# CH641 register map
Vendor: WCH Ltd.; File version: 1.0
Registers are 32-bit, read-write, reset 0x0 unless marked. A register's access mark holds for its fields unless they carry their own. Offsets are from the block's base; [hi:lo] are bit positions; {n}, {i} and the like mark numbered series; 'fields as' and 'values as' point back to an identical list.

## AFIO — Alternate function I/O
Base 0x40010000
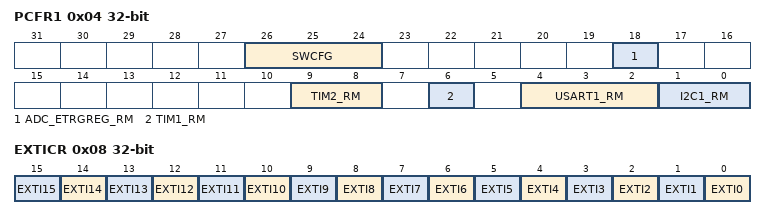
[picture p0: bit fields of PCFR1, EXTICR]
0x04 PCFR1 access per field — AF remap and debug I/O configuration register (AFIO_PCFR1)
  [26:24] SWCFG wo — Serial wire JTAG configuration
  [18] ADC_ETRGREG_RM rw — ADC External trigger injected conversion remapping
  [9:8] TIM2_RM rw — TIM2 remapping
  [6] TIM1_RM rw — TIM1 remapping
  [4:2] USART1_RM rw — USART1 remapping
  [1:0] I2C1_RM rw — I2C1 remapping
0x08 EXTICR — External interrupt configuration register (AFIO_EXTICR)
  [n] EXTI{n} (n=0..15) — EXTI{n} configuration

## EXTI
Base 0x40010400
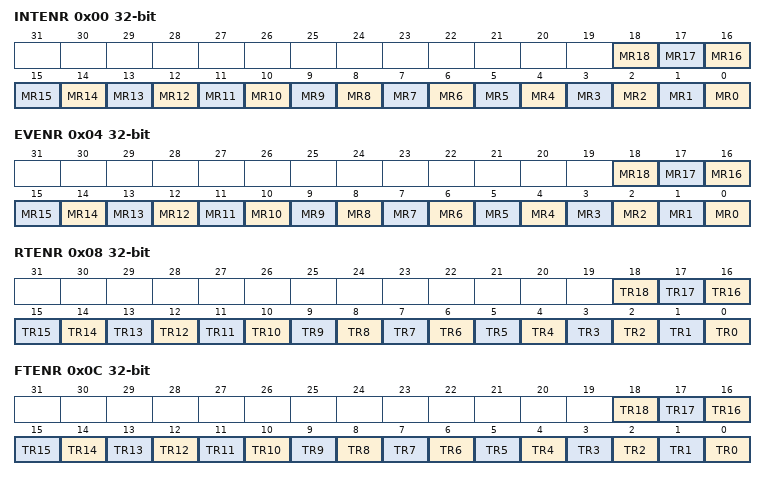
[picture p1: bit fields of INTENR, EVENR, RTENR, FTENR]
0x00 INTENR — Interrupt mask register (EXTI_INTENR)
  [n] MR{n} (n=0..18) — Interrupt Mask on line {n}
0x04 EVENR — Event mask register (EXTI_EVENR)
  [n] MR{n} (n=0..18) — Event Mask on line {n}
0x08 RTENR — Rising Trigger selection register (EXTI_RTENR)
  [n] TR{n} (n=0..18) — Rising trigger event configuration of line {n}
0x0C FTENR — Falling Trigger selection register (EXTI_FTENR)
  [n] TR{n} (n=0..18) — Falling trigger event configuration of line {n}
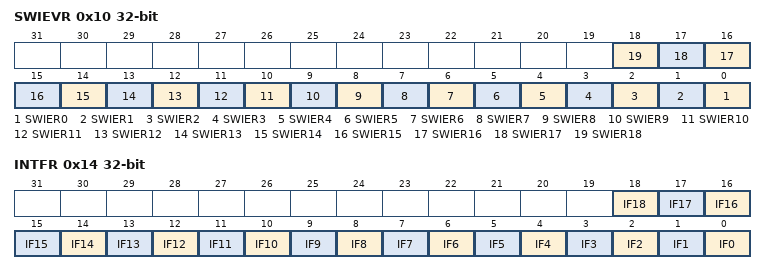
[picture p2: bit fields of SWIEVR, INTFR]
0x10 SWIEVR — Software interrupt event register (EXTI_SWIEVR)
  [n] SWIER{n} (n=0..18) — Software Interrupt on line {n}
0x14 INTFR — Pending register (EXTI_INTFR)
  [n] IF{n} (n=0..18) — Pending bit {n}

## DMA1 — DMA1 controller
Base 0x40020000
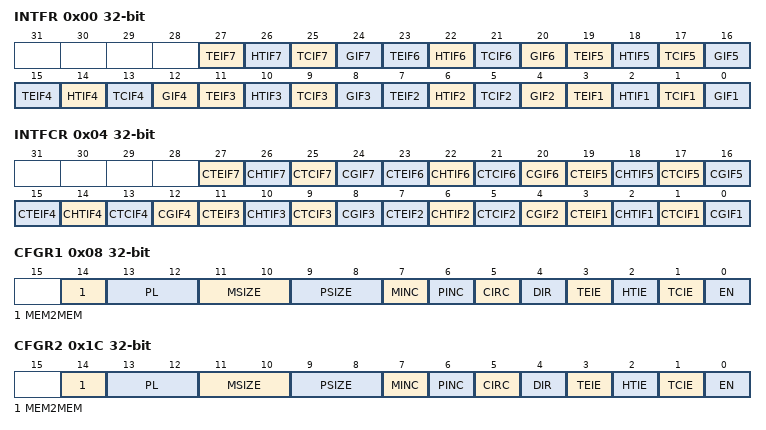
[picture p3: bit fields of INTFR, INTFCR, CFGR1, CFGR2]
0x00 INTFR ro — DMA interrupt status register (DMA_INTFR)
  [4n-1] TEIF{n} (n=1..7) — Channel {n} Transfer Error flag
  [4n-2] HTIF{n} (n=1..7) — Channel {n} Half Transfer Complete flag
  [4n-3] TCIF{n} (n=1..7) — Channel {n} Transfer Complete flag
  [4n-4] GIF{n} (n=1..7) — Channel {n} Global interrupt flag
0x04 INTFCR wo — DMA interrupt flag clear register (DMA_INTFCR)
  [4n-1] CTEIF{n} (n=1..7) — Channel {n} Transfer Error clear
  [4n-2] CHTIF{n} (n=1..7) — Channel {n} Half Transfer clear
  [4n-3] CTCIF{n} (n=1..7) — Channel {n} Transfer Complete clear
  [4n-4] CGIF{n} (n=1..7) — Channel {n} Global interrupt clear
0x08 CFGR1 — DMA channel configuration register (DMA_CFGR)
  [14] MEM2MEM — Memory to memory mode
  [13:12] PL — Channel Priority level
  [11:10] MSIZE — Memory size
  [9:8] PSIZE — Peripheral size
  [7] MINC — Memory increment mode
  [6] PINC — Peripheral increment mode
  [5] CIRC — Circular mode
  [4] DIR — Data transfer direction
  [3] TEIE — Transfer error interrupt enable
  [2] HTIE — Half Transfer interrupt enable
  [1] TCIE — Transfer complete interrupt enable
  [0] EN — Channel enable
0x0C CNTR1 — DMA channel 1 number of data register
  [15:0] NDT — Number of data to transfer
0x10 PADDR1 — DMA channel 1 peripheral address register
  [31:0] PA — Peripheral address
{0x0+0x14*i} MADDR{i} (i=1..7) — DMA channel {i} memory address register
  [31:0] MA — Memory address
0x1C CFGR2 — DMA channel configuration register (DMA_CFGR)
  fields as CFGR1
0x20 CNTR2 — DMA channel 2 number of data register
  [15:0] NDT — Number of data to transfer
0x24 PADDR2 — DMA channel 2 peripheral address register
  [31:0] PA — Peripheral address
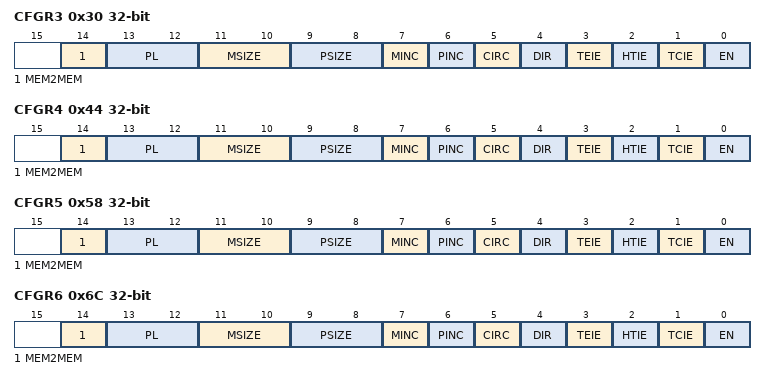
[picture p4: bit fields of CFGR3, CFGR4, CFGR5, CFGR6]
0x30 CFGR3 — DMA channel configuration register (DMA_CFGR)
  fields as CFGR1
0x34 CNTR3 — DMA channel 3 number of data register
  [15:0] NDT — Number of data to transfer
0x38 PADDR3 — DMA channel 3 peripheral address register
  [31:0] PA — Peripheral address
0x44 CFGR4 — DMA channel configuration register (DMA_CFGR)
  fields as CFGR1
0x48 CNTR4 — DMA channel 4 number of data register
  [15:0] NDT — Number of data to transfer
0x4C PADDR4 — DMA channel 4 peripheral address register
  [31:0] PA — Peripheral address
0x58 CFGR5 — DMA channel configuration register (DMA_CFGR)
  fields as CFGR1
0x5C CNTR5 — DMA channel 5 number of data register
  [15:0] NDT — Number of data to transfer
0x60 PADDR5 — DMA channel 5 peripheral address register
  [31:0] PA — Peripheral address
0x6C CFGR6 — DMA channel configuration register (DMA_CFGR)
  fields as CFGR1
0x70 CNTR6 — DMA channel 6 number of data register
  [15:0] NDT — Number of data to transfer
0x74 PADDR6 — DMA channel 6 peripheral address register
  [31:0] PA — Peripheral address
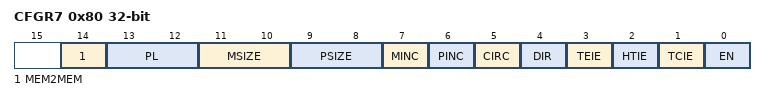
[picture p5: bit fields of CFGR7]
0x80 CFGR7 — DMA channel configuration register (DMA_CFGR)
  fields as CFGR1
0x84 CNTR7 — DMA channel 7 number of data register
  [15:0] NDT — Number of data to transfer
0x88 PADDR7 — DMA channel 7 peripheral address register
  [31:0] PA — Peripheral address
